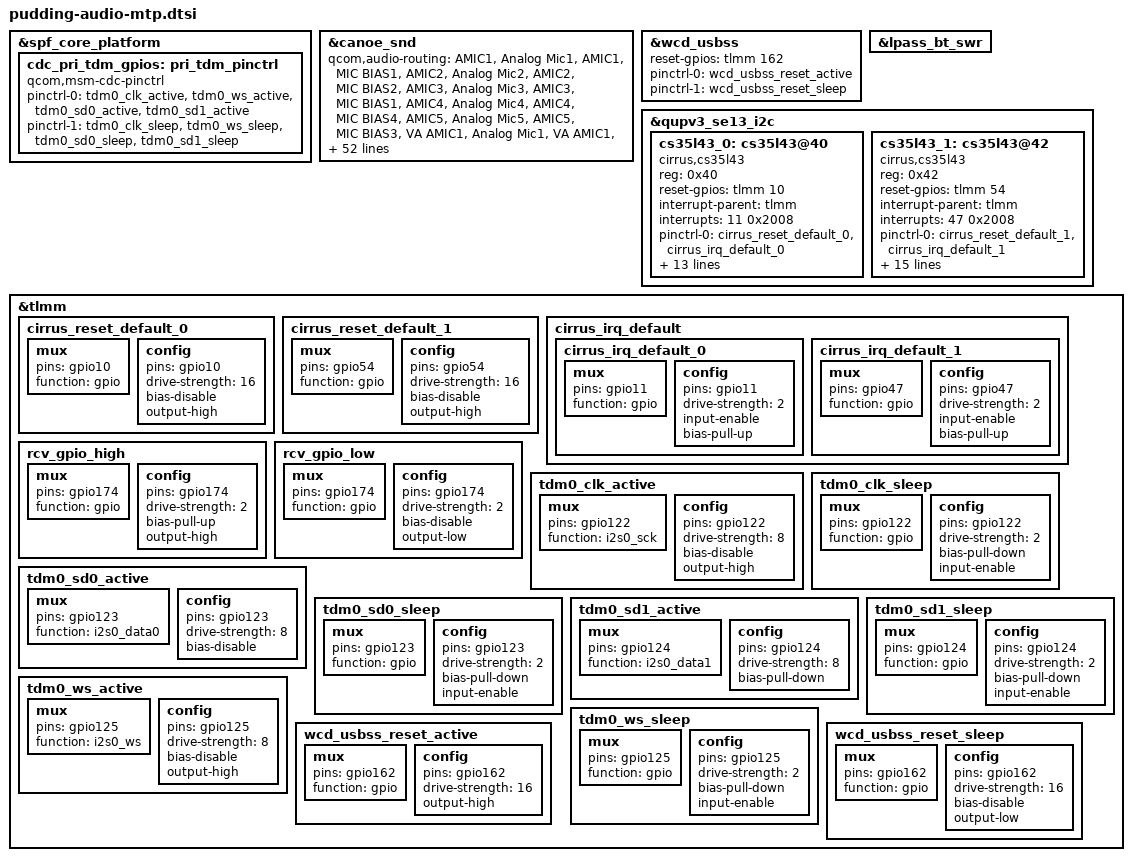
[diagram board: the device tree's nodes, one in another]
#include "xiaomi-sm8850-common.dtsi"

&spf_core_platform {
	cdc_pri_tdm_gpios: pri_tdm_pinctrl {
		compatible = "qcom,msm-cdc-pinctrl";
		pinctrl-names = "aud_active", "aud_sleep";
		pinctrl-0 = <&tdm0_clk_active &tdm0_ws_active &tdm0_sd0_active &tdm0_sd1_active>;
		pinctrl-1 = <&tdm0_clk_sleep &tdm0_ws_sleep &tdm0_sd0_sleep &tdm0_sd1_sleep>;
		#gpio-cells = <0>;
		status = "ok";
	};
};

&canoe_snd {
	qcom,audio-routing =
		"AMIC1", "Analog Mic1",
		"AMIC1", "MIC BIAS1",
		"AMIC2", "Analog Mic2",
		"AMIC2", "MIC BIAS2",
		"AMIC3", "Analog Mic3",
		"AMIC3", "MIC BIAS1",
		"AMIC4", "Analog Mic4",
		"AMIC4", "MIC BIAS4",
		"AMIC5", "Analog Mic5",
		"AMIC5", "MIC BIAS3",
		"VA AMIC1", "Analog Mic1",
		"VA AMIC1", "VA MIC BIAS1",
		"VA AMIC2", "Analog Mic2",
		"VA AMIC2", "VA MIC BIAS2",
		"VA AMIC3", "Analog Mic3",
		"VA AMIC3", "VA MIC BIAS3",
		"VA AMIC4", "Analog Mic4",
		"VA AMIC4", "VA MIC BIAS3",
		"VA AMIC5", "Analog Mic5",
		"VA AMIC5", "VA MIC BIAS4",
		"TX DMIC0", "Digital Mic0",
		"Digital Mic0", "MIC BIAS3",
		"TX DMIC1", "Digital Mic1",
		"Digital Mic1", "MIC BIAS3",
		"TX DMIC2", "Digital Mic2",
		"Digital Mic2", "MIC BIAS1",
		"TX DMIC3", "Digital Mic3",
		"Digital Mic3", "MIC BIAS1",
		"IN1_HPHL", "HPHL_OUT",
		"IN2_HPHR", "HPHR_OUT",
		"IN3_EAR", "AUX_OUT",
		"HAP_IN", "WSA2_HAPT OUT",
		"RX_TX DEC0_INP", "TX DEC0 MUX",
		"RX_TX DEC1_INP", "TX DEC1 MUX",
		"RX_TX DEC2_INP", "TX DEC2 MUX",
		"RX_TX DEC3_INP", "TX DEC3 MUX",
		"TX SWR_INPUT", "WCD_TX_OUTPUT",
		"VA SWR_INPUT", "VA_SWR_CLK",
		"VA SWR_INPUT", "WCD_TX_OUTPUT",
		"VA_AIF1 CAP", "VA_SWR_CLK",
		"VA_AIF2 CAP", "VA_SWR_CLK",
		"VA_AIF3 CAP", "VA_SWR_CLK",
		"VA DMIC0", "Digital Mic0",
		"VA DMIC1", "Digital Mic1",
		"VA DMIC2", "Digital Mic2",
		"VA DMIC3", "Digital Mic3",
		"Digital Mic0", "VA MIC BIAS3",
		"Digital Mic1", "VA MIC BIAS3",
		"Digital Mic2", "VA MIC BIAS1",
		"Digital Mic3", "VA MIC BIAS1";

	qcom,model = "canoe-mtp-snd-card";
	qcom,wsa-max-devs = <0>;
	qcom,mi2s-tdm-is-hw-vote-needed = <1>, <1>, <1>, <1>, <1>, <1>, <1>;
	qcom,tdm-max-slots = <2>;
	qcom,tdm-clk-attribute = <4>, <4>, <4>, <4>, <4>, <4>, <4>, <4>;
	qcom,audio-core-list = <0>, <1>;
	qcom,dedicated-wsa2;
	qcom,wcd-disable-legacy-surge;
	qcom,msm-mbhc-gnd-swh = <0>;
	qcom,msm-mbhc-hphl-swh = <0>;
	qcom,msm-mbhc-usbc-audio-supported = <0>;
	qcom,msm-mbhc-hs-mic-max-threshold-mv = <1670>;
	qcom,wcn-bt = <1>;
	qcom,ext-disp-audio-rx = <1>;
	qcom,tdm-audio-intf = <1>;
	qcom,pri-mi2s-gpios = <&cdc_pri_tdm_gpios>;
	wcd939x-i2c-handle = <&wcd_usbss>;
	asoc-codec = <&stub_codec>, <&lpass_cdc>,
		     <&wcd939x_codec>, <&swr_haptics>;
	asoc-codec-names = "msm-stub-codec.1", "lpass-cdc",
			   "wcd939x_codec", "swr-haptics";
	qcom,msm_audio_ssr_devs = <&audio_gpr>, <&lpi_tlmm>,
			<&lpass_cdc>, <&lpass_bt_swr>;
	qcom,upd_backends_used = "wsa";
	qcom,upd_lpass_reg_addr = <0x6B00418 0x6B14020>;
	qcom,upd_ear_pa_reg_addr = <0x3430>;
};

&wcd_usbss {
	reset-gpios = <&tlmm 162 0>;
	pinctrl-names = "usbss_active", "usbss_sleep";
	pinctrl-0 = <&wcd_usbss_reset_active>;
	pinctrl-1 = <&wcd_usbss_reset_sleep>;
};

&lpass_bt_swr {
	status = "ok";
};

&qupv3_se13_i2c {
	status = "ok";

	cs35l43_0: cs35l43@40 {
		compatible = "cirrus,cs35l43";
		reg = <0x40>;
		status = "ok";
		reset-gpios = <&tlmm 10 0>;
		interrupt-parent = <&tlmm>;
		interrupts = <11 0x2008>;
		pinctrl-names = "default";
		pinctrl-0 = <&cirrus_reset_default_0>, <&cirrus_irq_default_0>;
		cirrus,bst-ipk-ma = <4000>;
		cirrus,asp-sdout-hiz = <3>;
		cirrus,gpio2-src-sel = <4>;
		sound-name-prefix = "B";
		cirrus,i2c-addr = <0x28>;
		cirrus,low-pwr-mode-standby = <1>;
		cirrus,vpbr-enable = <1>;
		cirrus,vpbr-rel-rate = <0>;
		cirrus,vpbr-wait = <0>;
		cirrus,vpbr-atk-rate = <0>;
		cirrus,vpbr-atk-vol = <5>;
		cirrus,vpbr-max-att = <6>;
		cirrus,vpbr-thld = <4>;
	};

	cs35l43_1: cs35l43@42 {
		compatible = "cirrus,cs35l43";
		reg = <0x42>;
		status = "ok";
		reset-gpios = <&tlmm 54 0>;
		interrupt-parent = <&tlmm>;
		interrupts = <47 0x2008>;
		pinctrl-names = "default", "rcv_gpio_high", "rcv_gpio_low";
		pinctrl-0 = <&cirrus_reset_default_1>, <&cirrus_irq_default_1>;
		pinctrl-1 = <&rcv_gpio_high>;
		pinctrl-2 = <&rcv_gpio_low>;
		cirrus,bst-ipk-ma = <4000>;
		cirrus,asp-sdout-hiz = <3>;
		cirrus,gpio2-src-sel = <4>;
		sound-name-prefix = "T";
		cirrus,i2c-addr = <0x2a>;
		cirrus,low-pwr-mode-standby = <1>;
		cirrus,vpbr-enable = <1>;
		cirrus,vpbr-rel-rate = <0>;
		cirrus,vpbr-wait = <0>;
		cirrus,vpbr-atk-rate = <0>;
		cirrus,vpbr-atk-vol = <5>;
		cirrus,vpbr-max-att = <6>;
		cirrus,vpbr-thld = <4>;
	};
};

&tlmm {
	cirrus_reset_default_0: cirrus_reset_default_0 {
		mux {
			pins = "gpio10";
			function = "gpio";
		};
		config {
			pins = "gpio10";
			drive-strength = <16>;
			bias-disable;
			output-high;
		};
	};

	cirrus_reset_default_1: cirrus_reset_default_1 {
		mux {
			pins = "gpio54";
			function = "gpio";
		};
		config {
			pins = "gpio54";
			drive-strength = <16>;
			bias-disable;
			output-high;
		};
	};

	cirrus_irq_default {
		cirrus_irq_default_0: cirrus_irq_default_0 {
			mux {
				pins = "gpio11";
				function = "gpio";
			};
			config {
				pins = "gpio11";
				drive-strength = <2>;
				input-enable;
				bias-pull-up;
			};
		};

		cirrus_irq_default_1: cirrus_irq_default_1 {
			mux {
				pins = "gpio47";
				function = "gpio";
			};
			config {
				pins = "gpio47";
				drive-strength = <2>;
				input-enable;
				bias-pull-up;
			};
		};
	};

	rcv_gpio_high: rcv_gpio_high {
		mux {
			pins = "gpio174";
			function = "gpio";
		};
		config {
			pins = "gpio174";
			drive-strength = <2>;
			bias-pull-up;
			output-high;
		};
	};

	rcv_gpio_low: rcv_gpio_low {
		mux {
			pins = "gpio174";
			function = "gpio";
		};
		config {
			pins = "gpio174";
			drive-strength = <2>;
			bias-disable;
			output-low;
		};
	};

	tdm0_clk_active: tdm0_clk_active {
		mux {
			pins = "gpio122";
			function = "i2s0_sck";
		};
		config {
			pins = "gpio122";
			drive-strength = <8>;
			bias-disable;
			output-high;
		};
	};

	tdm0_clk_sleep: tdm0_clk_sleep {
		mux {
			pins = "gpio122";
			function = "gpio";
		};
		config {
			pins = "gpio122";
			drive-strength = <2>;
			bias-pull-down;
			input-enable;
		};
	};

	tdm0_sd0_active: tdm0_sd0_active {
		mux {
			pins = "gpio123";
			function = "i2s0_data0";
		};
		config {
			pins = "gpio123";
			drive-strength = <8>;
			bias-disable;
		};
	};

	tdm0_sd0_sleep: tdm0_sd0_sleep {
		mux {
			pins = "gpio123";
			function = "gpio";
		};
		config {
			pins = "gpio123";
			drive-strength = <2>;
			bias-pull-down;
			input-enable;
		};
	};

	tdm0_sd1_active: tdm0_sd1_active {
		mux {
			pins = "gpio124";
			function = "i2s0_data1";
		};
		config {
			pins = "gpio124";
			drive-strength = <8>;
			bias-pull-down;
		};
	};

	tdm0_sd1_sleep: tdm0_sd1_sleep {
		mux {
			pins = "gpio124";
			function = "gpio";
		};
		config {
			pins = "gpio124";
			drive-strength = <2>;
			bias-pull-down;
			input-enable;
		};
	};

	tdm0_ws_active: tdm0_ws_active {
		mux {
			pins = "gpio125";
			function = "i2s0_ws";
		};
		config {
			pins = "gpio125";
			drive-strength = <8>;
			bias-disable;
			output-high;
		};
	};

	tdm0_ws_sleep: tdm0_ws_sleep {
		mux {
			pins = "gpio125";
			function = "gpio";
		};
		config {
			pins = "gpio125";
			drive-strength = <2>;
			bias-pull-down;
			input-enable;
		};
	};

	wcd_usbss_reset_active: wcd_usbss_reset_active {
		mux {
			pins = "gpio162";
			function = "gpio";
		};
		config {
			pins = "gpio162";
			drive-strength = <16>;
			output-high;
		};
	};

	wcd_usbss_reset_sleep: wcd_usbss_reset_sleep {
		mux {
			pins = "gpio162";
			function = "gpio";
		};
		config {
			pins = "gpio162";
			drive-strength = <16>;
			bias-disable;
			output-low;
		};
	};
};

